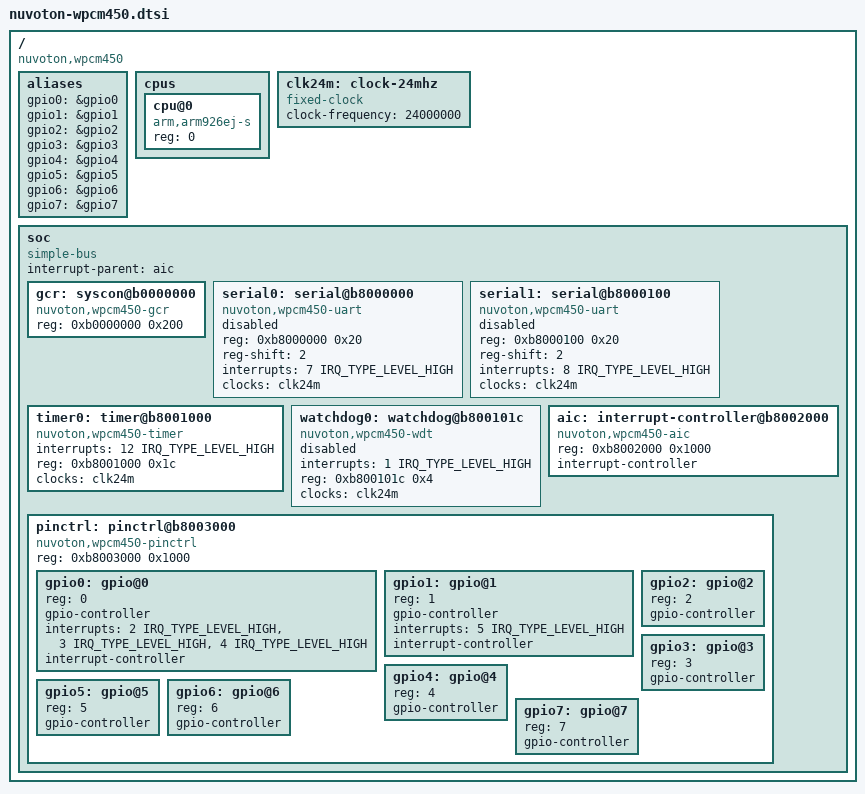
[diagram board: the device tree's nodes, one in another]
// SPDX-License-Identifier: GPL-2.0-only OR BSD-2-Clause
// Copyright 2021 Jonathan Neuschäfer

#include <dt-bindings/interrupt-controller/irq.h>

/ {
	compatible = "nuvoton,wpcm450";
	#address-cells = <1>;
	#size-cells = <1>;

	aliases {
		gpio0 = &gpio0;
		gpio1 = &gpio1;
		gpio2 = &gpio2;
		gpio3 = &gpio3;
		gpio4 = &gpio4;
		gpio5 = &gpio5;
		gpio6 = &gpio6;
		gpio7 = &gpio7;
	};

	cpus {
		#address-cells = <1>;
		#size-cells = <0>;

		cpu@0 {
			compatible = "arm,arm926ej-s";
			device_type = "cpu";
			reg = <0>;
		};
	};

	clk24m: clock-24mhz {
		/* 24 MHz dummy clock */
		compatible = "fixed-clock";
		clock-frequency = <24000000>;
		#clock-cells = <0>;
	};

	soc {
		compatible = "simple-bus";
		#address-cells = <1>;
		#size-cells = <1>;
		interrupt-parent = <&aic>;
		ranges;

		gcr: syscon@b0000000 {
			compatible = "nuvoton,wpcm450-gcr", "syscon", "simple-mfd";
			reg = <0xb0000000 0x200>;
		};

		serial0: serial@b8000000 {
			compatible = "nuvoton,wpcm450-uart";
			reg = <0xb8000000 0x20>;
			reg-shift = <2>;
			interrupts = <7 IRQ_TYPE_LEVEL_HIGH>;
			clocks = <&clk24m>;
			status = "disabled";
		};

		serial1: serial@b8000100 {
			compatible = "nuvoton,wpcm450-uart";
			reg = <0xb8000100 0x20>;
			reg-shift = <2>;
			interrupts = <8 IRQ_TYPE_LEVEL_HIGH>;
			clocks = <&clk24m>;
			status = "disabled";
		};

		timer0: timer@b8001000 {
			compatible = "nuvoton,wpcm450-timer";
			interrupts = <12 IRQ_TYPE_LEVEL_HIGH>;
			reg = <0xb8001000 0x1c>;
			clocks = <&clk24m>;
		};

		watchdog0: watchdog@b800101c {
			compatible = "nuvoton,wpcm450-wdt";
			interrupts = <1 IRQ_TYPE_LEVEL_HIGH>;
			reg = <0xb800101c 0x4>;
			clocks = <&clk24m>;
			status = "disabled";
		};

		aic: interrupt-controller@b8002000 {
			compatible = "nuvoton,wpcm450-aic";
			reg = <0xb8002000 0x1000>;
			interrupt-controller;
			#interrupt-cells = <2>;
		};

		pinctrl: pinctrl@b8003000 {
			compatible = "nuvoton,wpcm450-pinctrl";
			reg = <0xb8003000 0x1000>;
			#address-cells = <1>;
			#size-cells = <0>;

			gpio0: gpio@0 {
				reg = <0>;
				gpio-controller;
				#gpio-cells = <2>;
				interrupts = <2 IRQ_TYPE_LEVEL_HIGH>,
					     <3 IRQ_TYPE_LEVEL_HIGH>,
					     <4 IRQ_TYPE_LEVEL_HIGH>;
				interrupt-controller;
			};

			gpio1: gpio@1 {
				reg = <1>;
				gpio-controller;
				#gpio-cells = <2>;
				interrupts = <5 IRQ_TYPE_LEVEL_HIGH>;
				interrupt-controller;
			};

			gpio2: gpio@2 {
				reg = <2>;
				gpio-controller;
				#gpio-cells = <2>;
			};

			gpio3: gpio@3 {
				reg = <3>;
				gpio-controller;
				#gpio-cells = <2>;
			};

			gpio4: gpio@4 {
				reg = <4>;
				gpio-controller;
				#gpio-cells = <2>;
			};

			gpio5: gpio@5 {
				reg = <5>;
				gpio-controller;
				#gpio-cells = <2>;
			};

			gpio6: gpio@6 {
				reg = <6>;
				gpio-controller;
				#gpio-cells = <2>;
			};

			gpio7: gpio@7 {
				reg = <7>;
				gpio-controller;
				#gpio-cells = <2>;
			};
		};
	};
};
